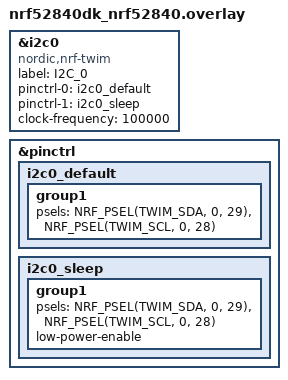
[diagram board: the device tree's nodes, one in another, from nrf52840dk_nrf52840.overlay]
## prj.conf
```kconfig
CONFIG_I2C=y
```

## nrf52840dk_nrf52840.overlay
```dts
// This overlay file allows the remapping of pins for buses that 
// go through GPIO pins

// remap what is disignated as i2c0
&i2c0 {
    // referenced when checking if device is ready in C code I think
	status = "okay";
    // compatible is needed, otherwise you'll get -ENOTSUP returns from some functions
	compatible = "nordic,nrf-twim";
	label = "I2C_0";
    // property that designates which pins to use
    // default is normal operation... sleep is low power?
	pinctrl-0 = <&i2c0_default>;
	pinctrl-1 = <&i2c0_sleep>;
	pinctrl-names = "default", "sleep";
    // doesn't matter as far as I know...
	clock-frequency = <100000>; 
};

// remap stuff within the pinctrl node
&pinctrl {
    // remap i2c0_default
	i2c0_default: i2c0_default{
		group1 {
            // within NRF_PSEL()...
            //      first arg is function of pin to remap
            //      second arg is gpio port of new pin (?)
            //      third arg is new pin within port to remap to
            //
            // psels = <NRF_PSEL(TWIM_SDA, 0, 29)>,
			//	<NRF_PSEL(TWIM_SCL, 0, 28)>;
            // Above will remap what is normally 0.4 and 0.3 to 0.29 and 0.28
            // Note that 0.4 and .3 might not be truly normal, I might've accidentally 
            // modified the nordic SDK file... whoopsies!
			psels = <NRF_PSEL(TWIM_SDA, 0, 29)>,
				<NRF_PSEL(TWIM_SCL, 0, 28)>;
		};
	};

	i2c0_sleep: i2c0_sleep{
		group1 {
			psels = <NRF_PSEL(TWIM_SDA, 0, 29)>,
				<NRF_PSEL(TWIM_SCL, 0, 28)>;
			low-power-enable;
		};
	};

};
```

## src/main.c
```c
#include <zephyr/kernel.h>

#include <stdio.h>
#include <string.h>
#include <stdlib.h>
#include <zephyr/device.h>
#include <zephyr/sys/printk.h>
#include <zephyr/drivers/i2c.h>


/*
Writes "CPM" to display, clears it, writes some number, clears that, repeats

CPM stands for counts per minute, and the m is really two lower case n's, since
the display can't really do an m.

*/

// define the node alias for i2c
#define I2C_NODE DT_ALIAS(i2c0)

// get the i2c0 device from dt
static const struct device *i2c0_dev = DEVICE_DT_GET(DT_NODELABEL(i2c0));

// random things to write to display
uint8_t count = 0;
uint8_t count2 = 1;
uint8_t cChar = 0x0C;
uint8_t pChar = 0x70; // shows "P"
uint8_t mChar = 0x4E; // shows "n", write twice to get m

// display clear command
uint8_t clear = 0x76;

int main(void)
{
        printk("Beginning main...\n\n");

        // check if i2c is ready to go
        if (!device_is_ready(i2c0_dev)) {
                printk("I2C device not ready :(\n");
                return 0;
        }

        while (1) {
                printk("Loop iteration...\n");

                // write clear command to display
                i2c_write(
                        i2c0_dev,       // i2c controller device
                        &clear,         // address of clear command
                        1,              // num bytes to write
                        0x71            // i2c target address
                );

                i2c_write(
                        i2c0_dev,
                        &cChar,
                        1,
                        0x71
                );

                i2c_write(
                        i2c0_dev,
                        &pChar,
                        1,
                        0x71
                );

                i2c_write(
                        i2c0_dev,
                        &mChar,
                        1,
                        0x71
                );

                i2c_write(
                        i2c0_dev,
                        &mChar,
                        1,
                        0x71
                );

                k_msleep(500);

                i2c_write(
                        i2c0_dev,
                        &clear,
                        1,
                        0x71
                );

                i2c_write(
                        i2c0_dev,
                        &count2,
                        1,
                        0x71
                );

                i2c_write(
                        i2c0_dev,
                        &count,
                        1,
                        0x71
                );
                
                k_msleep(500);
                
                if (count++ > 15) {
                        count = 0;
                }
        }



        return 0;
}
```
